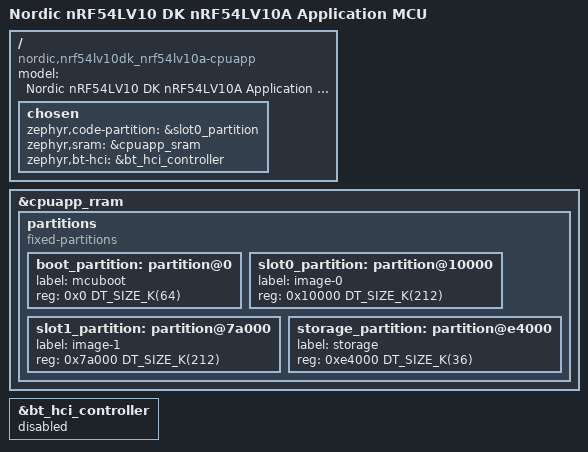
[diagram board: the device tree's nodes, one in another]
/*
 * Copyright (c) 2025 Nordic Semiconductor ASA
 *
 * SPDX-License-Identifier: LicenseRef-Nordic-5-Clause
 */

/dts-v1/;

#include "nrf54lv10a_cpuapp_common.dtsi"

/ {
	compatible = "nordic,nrf54lv10dk_nrf54lv10a-cpuapp";
	model = "Nordic nRF54LV10 DK nRF54LV10A Application MCU";

	chosen {
		zephyr,code-partition = &slot0_partition;
		zephyr,sram = &cpuapp_sram;
		zephyr,bt-hci = &bt_hci_controller;
	};
};

&cpuapp_rram {
	partitions {
		compatible = "fixed-partitions";
		#address-cells = <1>;
		#size-cells = <1>;
		ranges;

		boot_partition: partition@0 {
			label = "mcuboot";
			reg = <0x0 DT_SIZE_K(64)>;
		};

		slot0_partition: partition@10000 {
			label = "image-0";
			reg = <0x10000 DT_SIZE_K(212)>;
		};

		slot1_partition: partition@7a000 {
			label = "image-1";
			reg = <0x7a000 DT_SIZE_K(212)>;
		};

		storage_partition: partition@e4000 {
			label = "storage";
			reg = <0xe4000 DT_SIZE_K(36)>;
		};
	};
};

&bt_hci_controller {
	status = "okay";
};

&bt_hci_controller {
	status = "disabled";
};
